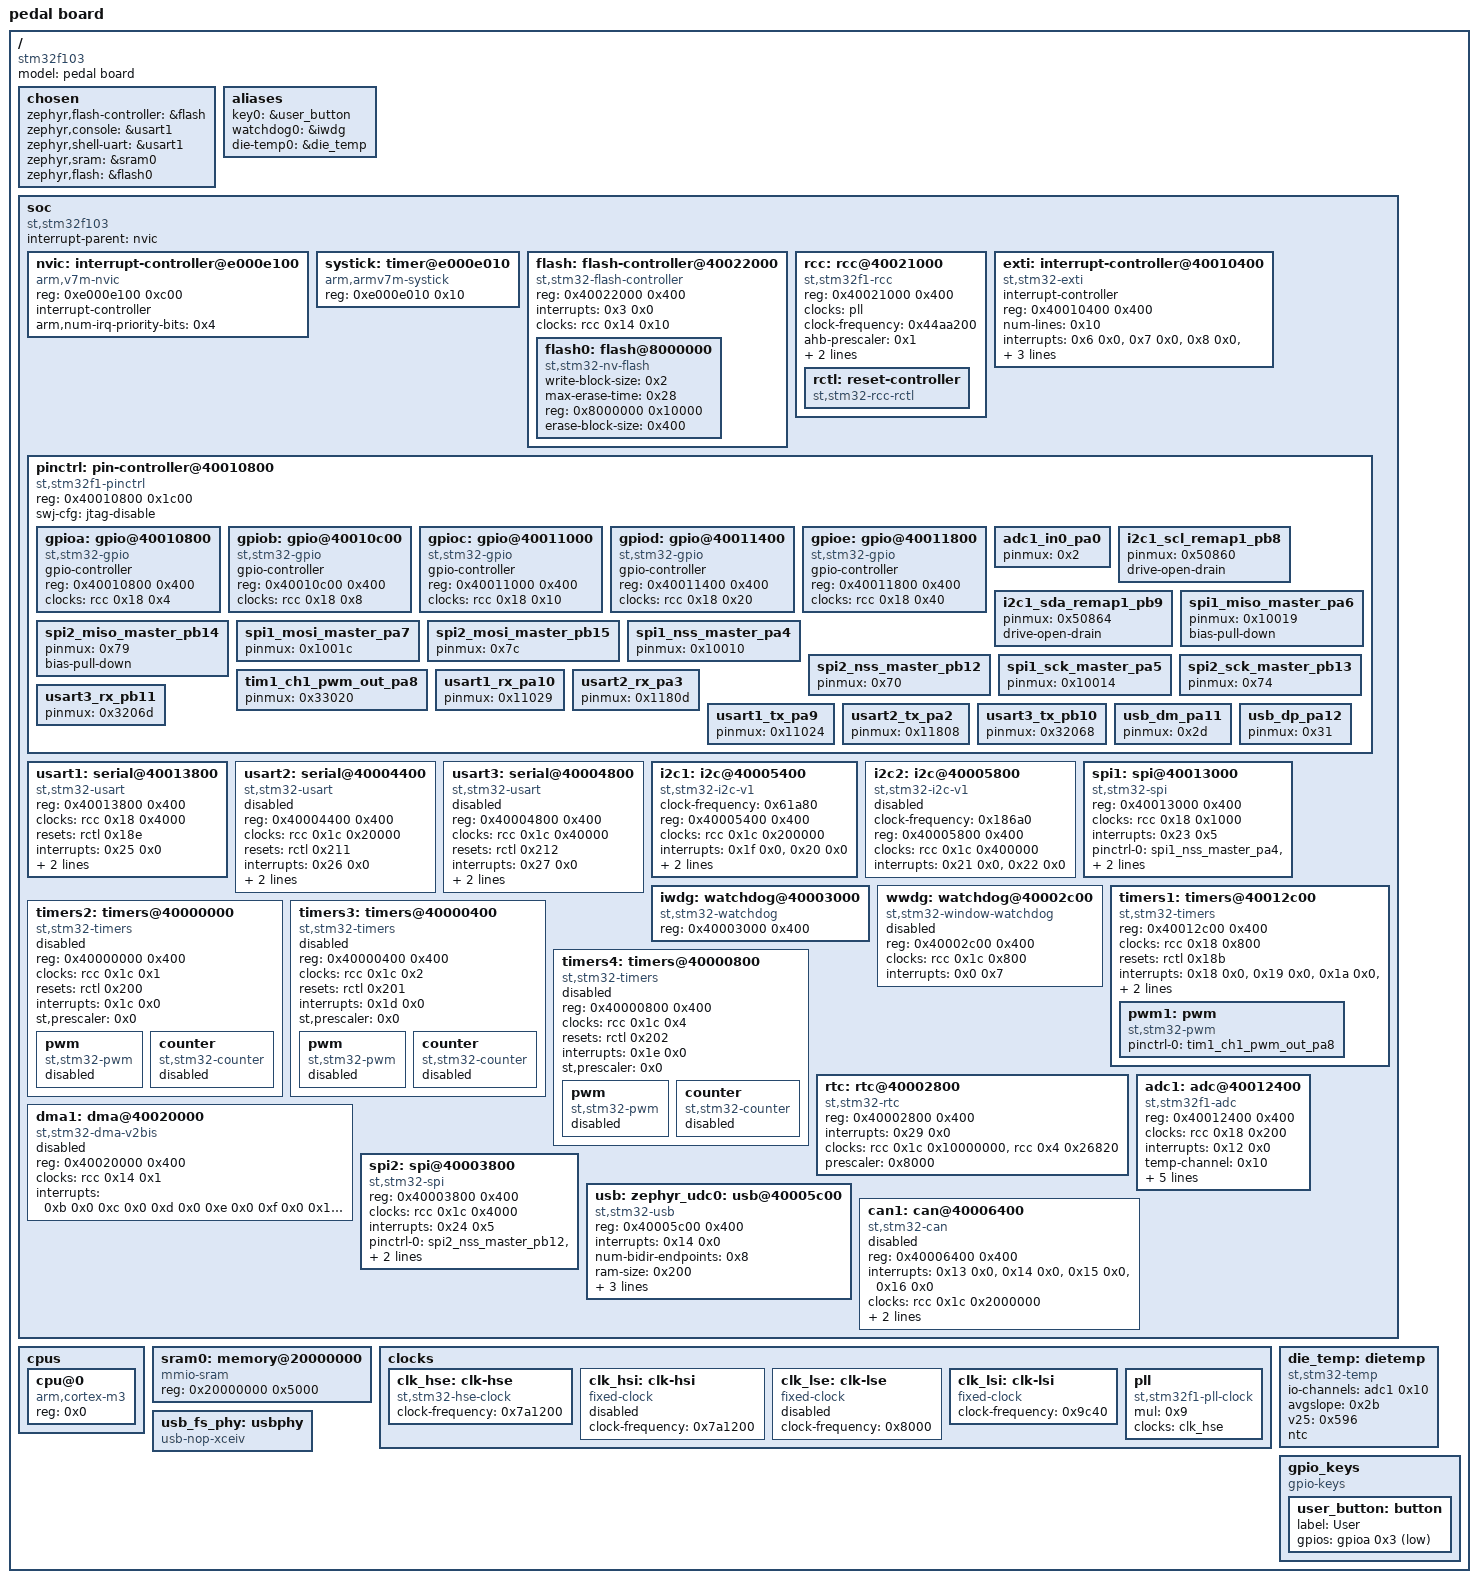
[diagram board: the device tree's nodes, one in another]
/dts-v1/;

/ {
	#address-cells = < 0x1 >;
	#size-cells = < 0x1 >;
	model = "pedal board";
	compatible = "stm32f103";
	chosen {
		zephyr,flash-controller = &flash;
		zephyr,console = &usart1;
		zephyr,shell-uart = &usart1;
		zephyr,sram = &sram0;
		zephyr,flash = &flash0;
	};
	aliases {
		key0 = &user_button;
		watchdog0 = &iwdg;
		die-temp0 = &die_temp;
	};
	soc {
		#address-cells = < 0x1 >;
		#size-cells = < 0x1 >;
		compatible = "st,stm32f103", "st,stm32f1", "simple-bus";
		interrupt-parent = < &nvic >;
		ranges;
		nvic: interrupt-controller@e000e100 {
			#address-cells = < 0x1 >;
			compatible = "arm,v7m-nvic";
			reg = < 0xe000e100 0xc00 >;
			interrupt-controller;
			#interrupt-cells = < 0x2 >;
			arm,num-irq-priority-bits = < 0x4 >;
			phandle = < 0x1 >;
		};
		systick: timer@e000e010 {
			compatible = "arm,armv7m-systick";
			reg = < 0xe000e010 0x10 >;
		};
		flash: flash-controller@40022000 {
			compatible = "st,stm32-flash-controller", "st,stm32f1-flash-controller";
			reg = < 0x40022000 0x400 >;
			interrupts = < 0x3 0x0 >;
			clocks = < &rcc 0x14 0x10 >;
			#address-cells = < 0x1 >;
			#size-cells = < 0x1 >;
			flash0: flash@8000000 {
				compatible = "st,stm32-nv-flash", "soc-nv-flash";
				write-block-size = < 0x2 >;
				max-erase-time = < 0x28 >;
				reg = < 0x8000000 0x10000 >;
				erase-block-size = < 0x400 >;
			};
		};
		rcc: rcc@40021000 {
			compatible = "st,stm32f1-rcc";
			#clock-cells = < 0x2 >;
			reg = < 0x40021000 0x400 >;
			clocks = < &pll >;
			clock-frequency = < 0x44aa200 >;
			ahb-prescaler = < 0x1 >;
			apb1-prescaler = < 0x2 >;
			apb2-prescaler = < 0x1 >;
			phandle = < 0x2 >;
			rctl: reset-controller {
				compatible = "st,stm32-rcc-rctl";
				#reset-cells = < 0x1 >;
				phandle = < 0x4 >;
			};
		};
		exti: interrupt-controller@40010400 {
			compatible = "st,stm32-exti";
			interrupt-controller;
			#interrupt-cells = < 0x1 >;
			#address-cells = < 0x1 >;
			reg = < 0x40010400 0x400 >;
			num-lines = < 0x10 >;
			interrupts = < 0x6 0x0 >, < 0x7 0x0 >, < 0x8 0x0 >, < 0x9 0x0 >, < 0xa 0x0 >, < 0x17 0x0 >, < 0x28 0x0 >;
			interrupt-names = "line0", "line1", "line2", "line3", "line4", "line5-9", "line10-15";
			line-ranges = < 0x0 0x1 >, < 0x1 0x1 >, < 0x2 0x1 >, < 0x3 0x1 >, < 0x4 0x1 >, < 0x5 0x5 >, < 0xa 0x6 >;
		};
		pinctrl: pin-controller@40010800 {
			compatible = "st,stm32f1-pinctrl";
			#address-cells = < 0x1 >;
			#size-cells = < 0x1 >;
			reg = < 0x40010800 0x1c00 >;
			swj-cfg = "jtag-disable";
			gpioa: gpio@40010800 {
				compatible = "st,stm32-gpio";
				gpio-controller;
				#gpio-cells = < 0x2 >;
				reg = < 0x40010800 0x400 >;
				clocks = < &rcc 0x18 0x4 >;
				phandle = < 0x1c >;
			};
			gpiob: gpio@40010c00 {
				compatible = "st,stm32-gpio";
				gpio-controller;
				#gpio-cells = < 0x2 >;
				reg = < 0x40010c00 0x400 >;
				clocks = < &rcc 0x18 0x8 >;
			};
			gpioc: gpio@40011000 {
				compatible = "st,stm32-gpio";
				gpio-controller;
				#gpio-cells = < 0x2 >;
				reg = < 0x40011000 0x400 >;
				clocks = < &rcc 0x18 0x10 >;
			};
			gpiod: gpio@40011400 {
				compatible = "st,stm32-gpio";
				gpio-controller;
				#gpio-cells = < 0x2 >;
				reg = < 0x40011400 0x400 >;
				clocks = < &rcc 0x18 0x20 >;
			};
			gpioe: gpio@40011800 {
				compatible = "st,stm32-gpio";
				gpio-controller;
				#gpio-cells = < 0x2 >;
				reg = < 0x40011800 0x400 >;
				clocks = < &rcc 0x18 0x40 >;
			};
			adc1_in0_pa0: adc1_in0_pa0 {
				pinmux = < 0x2 >;
				phandle = < 0x12 >;
			};
			i2c1_scl_remap1_pb8: i2c1_scl_remap1_pb8 {
				pinmux = < 0x50860 >;
				drive-open-drain;
				phandle = < 0xb >;
			};
			i2c1_sda_remap1_pb9: i2c1_sda_remap1_pb9 {
				pinmux = < 0x50864 >;
				drive-open-drain;
				phandle = < 0xc >;
			};
			spi1_miso_master_pa6: spi1_miso_master_pa6 {
				pinmux = < 0x10019 >;
				bias-pull-down;
				phandle = < 0xf >;
			};
			spi2_miso_master_pb14: spi2_miso_master_pb14 {
				pinmux = < 0x79 >;
				bias-pull-down;
				phandle = < 0x15 >;
			};
			spi1_mosi_master_pa7: spi1_mosi_master_pa7 {
				pinmux = < 0x1001c >;
				phandle = < 0x10 >;
			};
			spi2_mosi_master_pb15: spi2_mosi_master_pb15 {
				pinmux = < 0x7c >;
				phandle = < 0x16 >;
			};
			spi1_nss_master_pa4: spi1_nss_master_pa4 {
				pinmux = < 0x10010 >;
				phandle = < 0xd >;
			};
			spi2_nss_master_pb12: spi2_nss_master_pb12 {
				pinmux = < 0x70 >;
				phandle = < 0x13 >;
			};
			spi1_sck_master_pa5: spi1_sck_master_pa5 {
				pinmux = < 0x10014 >;
				phandle = < 0xe >;
			};
			spi2_sck_master_pb13: spi2_sck_master_pb13 {
				pinmux = < 0x74 >;
				phandle = < 0x14 >;
			};
			tim1_ch1_pwm_out_pa8: tim1_ch1_pwm_out_pa8 {
				pinmux = < 0x33020 >;
				phandle = < 0x11 >;
			};
			usart1_rx_pa10: usart1_rx_pa10 {
				pinmux = < 0x11029 >;
				phandle = < 0x6 >;
			};
			usart2_rx_pa3: usart2_rx_pa3 {
				pinmux = < 0x1180d >;
				phandle = < 0x8 >;
			};
			usart3_rx_pb11: usart3_rx_pb11 {
				pinmux = < 0x3206d >;
				phandle = < 0xa >;
			};
			usart1_tx_pa9: usart1_tx_pa9 {
				pinmux = < 0x11024 >;
				phandle = < 0x5 >;
			};
			usart2_tx_pa2: usart2_tx_pa2 {
				pinmux = < 0x11808 >;
				phandle = < 0x7 >;
			};
			usart3_tx_pb10: usart3_tx_pb10 {
				pinmux = < 0x32068 >;
				phandle = < 0x9 >;
			};
			usb_dm_pa11: usb_dm_pa11 {
				pinmux = < 0x2d >;
				phandle = < 0x18 >;
			};
			usb_dp_pa12: usb_dp_pa12 {
				pinmux = < 0x31 >;
				phandle = < 0x19 >;
			};
		};
		usart1: serial@40013800 {
			compatible = "st,stm32-usart", "st,stm32-uart";
			reg = < 0x40013800 0x400 >;
			clocks = < &rcc 0x18 0x4000 >;
			resets = < &rctl 0x18e >;
			interrupts = < 0x25 0x0 >;
			status = "okay";
			pinctrl-0 = < &usart1_tx_pa9 &usart1_rx_pa10 >;
			pinctrl-names = "default";
			current-speed = < 0x1c200 >;
		};
		usart2: serial@40004400 {
			compatible = "st,stm32-usart", "st,stm32-uart";
			reg = < 0x40004400 0x400 >;
			clocks = < &rcc 0x1c 0x20000 >;
			resets = < &rctl 0x211 >;
			interrupts = < 0x26 0x0 >;
			status = "disabled";
			pinctrl-0 = < &usart2_tx_pa2 &usart2_rx_pa3 >;
			pinctrl-names = "default";
			current-speed = < 0x1c200 >;
		};
		usart3: serial@40004800 {
			compatible = "st,stm32-usart", "st,stm32-uart";
			reg = < 0x40004800 0x400 >;
			clocks = < &rcc 0x1c 0x40000 >;
			resets = < &rctl 0x212 >;
			interrupts = < 0x27 0x0 >;
			status = "disabled";
			pinctrl-0 = < &usart3_tx_pb10 &usart3_rx_pb11 >;
			pinctrl-names = "default";
			current-speed = < 0x1c200 >;
		};
		i2c1: i2c@40005400 {
			compatible = "st,stm32-i2c-v1";
			clock-frequency = < 0x61a80 >;
			#address-cells = < 0x1 >;
			#size-cells = < 0x0 >;
			reg = < 0x40005400 0x400 >;
			clocks = < &rcc 0x1c 0x200000 >;
			interrupts = < 0x1f 0x0 >, < 0x20 0x0 >;
			interrupt-names = "event", "error";
			status = "okay";
			pinctrl-0 = < &i2c1_scl_remap1_pb8 &i2c1_sda_remap1_pb9 >;
			pinctrl-names = "default";
		};
		i2c2: i2c@40005800 {
			compatible = "st,stm32-i2c-v1";
			clock-frequency = < 0x186a0 >;
			#address-cells = < 0x1 >;
			#size-cells = < 0x0 >;
			reg = < 0x40005800 0x400 >;
			clocks = < &rcc 0x1c 0x400000 >;
			interrupts = < 0x21 0x0 >, < 0x22 0x0 >;
			interrupt-names = "event", "error";
			status = "disabled";
		};
		spi1: spi@40013000 {
			compatible = "st,stm32-spi";
			#address-cells = < 0x1 >;
			#size-cells = < 0x0 >;
			reg = < 0x40013000 0x400 >;
			clocks = < &rcc 0x18 0x1000 >;
			interrupts = < 0x23 0x5 >;
			status = "okay";
			pinctrl-0 = < &spi1_nss_master_pa4 &spi1_sck_master_pa5 &spi1_miso_master_pa6 &spi1_mosi_master_pa7 >;
			pinctrl-names = "default";
		};
		iwdg: watchdog@40003000 {
			compatible = "st,stm32-watchdog";
			reg = < 0x40003000 0x400 >;
			status = "okay";
		};
		wwdg: watchdog@40002c00 {
			compatible = "st,stm32-window-watchdog";
			reg = < 0x40002c00 0x400 >;
			clocks = < &rcc 0x1c 0x800 >;
			interrupts = < 0x0 0x7 >;
			status = "disabled";
		};
		timers1: timers@40012c00 {
			compatible = "st,stm32-timers";
			reg = < 0x40012c00 0x400 >;
			clocks = < &rcc 0x18 0x800 >;
			resets = < &rctl 0x18b >;
			interrupts = < 0x18 0x0 >, < 0x19 0x0 >, < 0x1a 0x0 >, < 0x1b 0x0 >;
			interrupt-names = "brk", "up", "trgcom", "cc";
			st,prescaler = < 0x2710 >;
			status = "okay";
			pwm1: pwm {
				compatible = "st,stm32-pwm";
				status = "okay";
				#pwm-cells = < 0x3 >;
				pinctrl-0 = < &tim1_ch1_pwm_out_pa8 >;
				pinctrl-names = "default";
			};
		};
		timers2: timers@40000000 {
			compatible = "st,stm32-timers";
			reg = < 0x40000000 0x400 >;
			clocks = < &rcc 0x1c 0x1 >;
			resets = < &rctl 0x200 >;
			interrupts = < 0x1c 0x0 >;
			interrupt-names = "global";
			st,prescaler = < 0x0 >;
			status = "disabled";
			pwm {
				compatible = "st,stm32-pwm";
				status = "disabled";
				#pwm-cells = < 0x3 >;
			};
			counter {
				compatible = "st,stm32-counter";
				status = "disabled";
			};
		};
		timers3: timers@40000400 {
			compatible = "st,stm32-timers";
			reg = < 0x40000400 0x400 >;
			clocks = < &rcc 0x1c 0x2 >;
			resets = < &rctl 0x201 >;
			interrupts = < 0x1d 0x0 >;
			interrupt-names = "global";
			st,prescaler = < 0x0 >;
			status = "disabled";
			pwm {
				compatible = "st,stm32-pwm";
				status = "disabled";
				#pwm-cells = < 0x3 >;
			};
			counter {
				compatible = "st,stm32-counter";
				status = "disabled";
			};
		};
		timers4: timers@40000800 {
			compatible = "st,stm32-timers";
			reg = < 0x40000800 0x400 >;
			clocks = < &rcc 0x1c 0x4 >;
			resets = < &rctl 0x202 >;
			interrupts = < 0x1e 0x0 >;
			interrupt-names = "global";
			st,prescaler = < 0x0 >;
			status = "disabled";
			pwm {
				compatible = "st,stm32-pwm";
				status = "disabled";
				#pwm-cells = < 0x3 >;
			};
			counter {
				compatible = "st,stm32-counter";
				status = "disabled";
			};
		};
		rtc: rtc@40002800 {
			compatible = "st,stm32-rtc";
			reg = < 0x40002800 0x400 >;
			interrupts = < 0x29 0x0 >;
			clocks = < &rcc 0x1c 0x10000000 >, < &rcc 0x4 0x26820 >;
			prescaler = < 0x8000 >;
			status = "okay";
		};
		adc1: adc@40012400 {
			compatible = "st,stm32f1-adc", "st,stm32-adc";
			reg = < 0x40012400 0x400 >;
			clocks = < &rcc 0x18 0x200 >;
			interrupts = < 0x12 0x0 >;
			status = "okay";
			#io-channel-cells = < 0x1 >;
			temp-channel = < 0x10 >;
			vref-channel = < 0x11 >;
			resolutions = < 0x6000ff >;
			sampling-times = < 0x2 0x8 0xe 0x1d 0x2a 0x38 0x48 0xf0 >;
			pinctrl-0 = < &adc1_in0_pa0 >;
			pinctrl-names = "default";
			phandle = < 0x1b >;
		};
		dma1: dma@40020000 {
			compatible = "st,stm32-dma-v2bis";
			#dma-cells = < 0x2 >;
			reg = < 0x40020000 0x400 >;
			clocks = < &rcc 0x14 0x1 >;
			interrupts = < 0xb 0x0 0xc 0x0 0xd 0x0 0xe 0x0 0xf 0x0 0x10 0x0 0x11 0x0 >;
			status = "disabled";
		};
		spi2: spi@40003800 {
			compatible = "st,stm32-spi";
			#address-cells = < 0x1 >;
			#size-cells = < 0x0 >;
			reg = < 0x40003800 0x400 >;
			clocks = < &rcc 0x1c 0x4000 >;
			interrupts = < 0x24 0x5 >;
			status = "okay";
			pinctrl-0 = < &spi2_nss_master_pb12 &spi2_sck_master_pb13 &spi2_miso_master_pb14 &spi2_mosi_master_pb15 >;
			pinctrl-names = "default";
		};
		usb: zephyr_udc0: usb@40005c00 {
			compatible = "st,stm32-usb";
			reg = < 0x40005c00 0x400 >;
			interrupts = < 0x14 0x0 >;
			interrupt-names = "usb";
			num-bidir-endpoints = < 0x8 >;
			ram-size = < 0x200 >;
			status = "okay";
			clocks = < &rcc 0x1c 0x800000 >;
			phys = < &usb_fs_phy >;
			pinctrl-0 = < &usb_dm_pa11 &usb_dp_pa12 >;
			pinctrl-names = "default";
		};
		can1: can@40006400 {
			compatible = "st,stm32-can";
			reg = < 0x40006400 0x400 >;
			interrupts = < 0x13 0x0 >, < 0x14 0x0 >, < 0x15 0x0 >, < 0x16 0x0 >;
			interrupt-names = "TX", "RX0", "RX1", "SCE";
			clocks = < &rcc 0x1c 0x2000000 >;
			status = "disabled";
			sjw = < 0x1 >;
			sample-point = < 0x36b >;
		};
	};
	cpus {
		#address-cells = < 0x1 >;
		#size-cells = < 0x0 >;
		cpu@0 {
			device_type = "cpu";
			compatible = "arm,cortex-m3";
			reg = < 0x0 >;
		};
	};
	sram0: memory@20000000 {
		compatible = "mmio-sram";
		reg = < 0x20000000 0x5000 >;
	};
	clocks {
		clk_hse: clk-hse {
			#clock-cells = < 0x0 >;
			compatible = "st,stm32-hse-clock";
			status = "okay";
			clock-frequency = < 0x7a1200 >;
			phandle = < 0x1a >;
		};
		clk_hsi: clk-hsi {
			#clock-cells = < 0x0 >;
			compatible = "fixed-clock";
			clock-frequency = < 0x7a1200 >;
			status = "disabled";
		};
		clk_lse: clk-lse {
			#clock-cells = < 0x0 >;
			compatible = "fixed-clock";
			clock-frequency = < 0x8000 >;
			status = "disabled";
		};
		clk_lsi: clk-lsi {
			#clock-cells = < 0x0 >;
			compatible = "fixed-clock";
			clock-frequency = < 0x9c40 >;
			status = "okay";
		};
		pll: pll {
			#clock-cells = < 0x0 >;
			compatible = "st,stm32f1-pll-clock";
			status = "okay";
			mul = < 0x9 >;
			clocks = < &clk_hse >;
			phandle = < 0x3 >;
		};
	};
	die_temp: dietemp {
		compatible = "st,stm32-temp";
		io-channels = < &adc1 0x10 >;
		status = "okay";
		avgslope = < 0x2b >;
		v25 = < 0x596 >;
		ntc;
	};
	usb_fs_phy: usbphy {
		compatible = "usb-nop-xceiv";
		#phy-cells = < 0x0 >;
		phandle = < 0x17 >;
	};
	gpio_keys {
		compatible = "gpio-keys";
		user_button: button {
			label = "User";
			gpios = < &gpioa 0x3 0x1 >;
		};
	};
};
